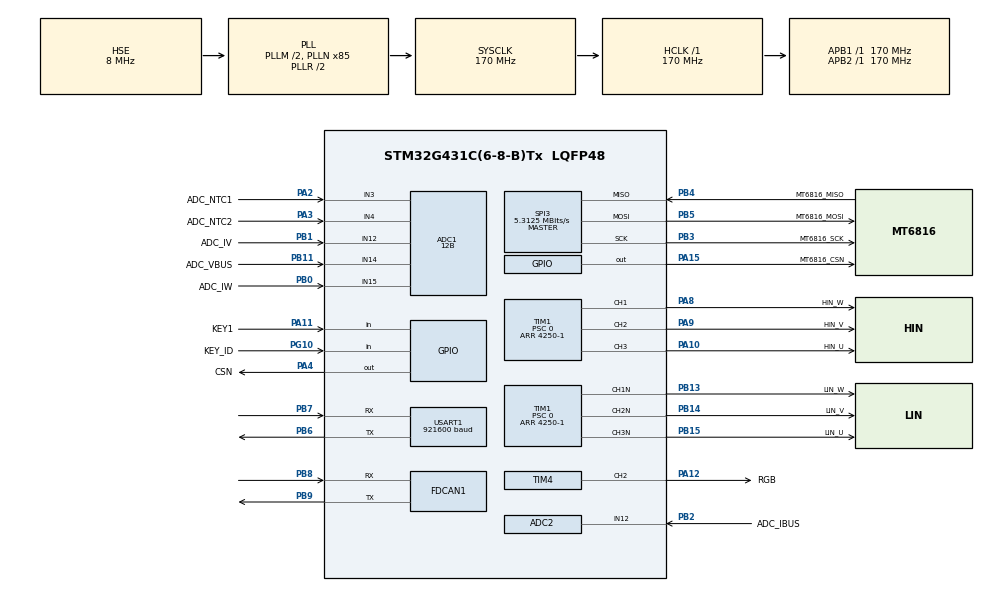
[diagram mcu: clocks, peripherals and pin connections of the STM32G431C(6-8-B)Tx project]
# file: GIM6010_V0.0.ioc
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ADC1.Channel-0\#ChannelRegularConversion=ADC_CHANNEL_14
ADC1.Channel-1\#ChannelRegularConversion=ADC_CHANNEL_3
ADC1.Channel-2\#ChannelRegularConversion=ADC_CHANNEL_4
ADC1.ContinuousConvMode=DISABLE
ADC1.DMAContinuousRequests=DISABLE
ADC1.DiscontinuousConvMode=DISABLE
ADC1.EOCSelection=ADC_EOC_SEQ_CONV
ADC1.EnableInjectedConversion=ENABLE
ADC1.EnableRegularConversion=ENABLE
ADC1.ExternalTrigConv=ADC_SOFTWARE_START
ADC1.ExternalTrigConvEdge=ADC_EXTERNALTRIGCONVEDGE_NONE
ADC1.ExternalTrigInjecConv=ADC_EXTERNALTRIGINJEC_T1_CC4
ADC1.ExternalTrigInjecConvEdge=ADC_EXTERNALTRIGINJECCONV_EDGE_RISING
ADC1.InjNumberOfConversion=3
ADC1.InjectedChannel-1\#ChannelInjectedConversion=ADC_CHANNEL_12
ADC1.InjectedChannel-2\#ChannelInjectedConversion=ADC_CHANNEL_15
ADC1.InjectedChannel-3\#ChannelInjectedConversion=ADC_CHANNEL_14
ADC1.InjectedConvMode=None
ADC1.InjectedOffsetNumber-1\#ChannelInjectedConversion=ADC_OFFSET_NONE
ADC1.InjectedOffsetNumber-2\#ChannelInjectedConversion=ADC_OFFSET_NONE
ADC1.InjectedOffsetNumber-3\#ChannelInjectedConversion=ADC_OFFSET_NONE
ADC1.InjectedRank-1\#ChannelInjectedConversion=1
ADC1.InjectedRank-2\#ChannelInjectedConversion=2
ADC1.InjectedRank-3\#ChannelInjectedConversion=3
ADC1.InjectedSamplingTime-1\#ChannelInjectedConversion=ADC_SAMPLETIME_47CYCLES_5
ADC1.InjectedSamplingTime-2\#ChannelInjectedConversion=ADC_SAMPLETIME_47CYCLES_5
ADC1.InjectedSamplingTime-3\#ChannelInjectedConversion=ADC_SAMPLETIME_47CYCLES_5
ADC1.LowPowerAutoWait=DISABLE
ADC1.NbrOfConversion=3
ADC1.NbrOfConversionFlag=1
ADC1.OffsetNumber-0\#ChannelRegularConversion=ADC_OFFSET_NONE
ADC1.OffsetNumber-1\#ChannelRegularConversion=ADC_OFFSET_NONE
ADC1.OffsetNumber-2\#ChannelRegularConversion=ADC_OFFSET_NONE
ADC1.Overrun=ADC_OVR_DATA_PRESERVED
ADC1.Rank-0\#ChannelRegularConversion=1
ADC1.Rank-1\#ChannelRegularConversion=2
ADC1.Rank-2\#ChannelRegularConversion=3
ADC1.Resolution=ADC_RESOLUTION_12B
ADC1.SamplingTime-0\#ChannelRegularConversion=ADC_SAMPLETIME_47CYCLES_5
ADC1.SamplingTime-1\#ChannelRegularConversion=ADC_SAMPLETIME_47CYCLES_5
ADC1.SamplingTime-2\#ChannelRegularConversion=ADC_SAMPLETIME_47CYCLES_5
ADC1.ScanConvMode=ADC_SCAN_ENABLE
ADC1.SingleDiff-1\#ChannelInjectedConversion=ADC_SINGLE_ENDED
ADC1.SingleDiff-2\#ChannelInjectedConversion=ADC_SINGLE_ENDED
ADC1.SingleDiff-3\#ChannelInjectedConversion=ADC_SINGLE_ENDED
ADC1.master=1
ADC2.Channel-0\#ChannelRegularConversion=ADC_CHANNEL_12
ADC2.ContinuousConvMode=DISABLE
ADC2.DiscontinuousConvMode=DISABLE
ADC2.EnableInjectedConversion=DISABLE
ADC2.EnableRegularConversion=ENABLE
ADC2.ExternalTrigConv=ADC_SOFTWARE_START
ADC2.ExternalTrigConvEdge=ADC_EXTERNALTRIGCONVEDGE_NONE
ADC2.NbrOfConversionFlag=1
ADC2.OffsetNumber-0\#ChannelRegularConversion=ADC_OFFSET_NONE
ADC2.Overrun=ADC_OVR_DATA_PRESERVED
ADC2.Rank-0\#ChannelRegularConversion=1
ADC2.Resolution=ADC_RESOLUTION_12B
ADC2.SamplingTime-0\#ChannelRegularConversion=ADC_SAMPLETIME_47CYCLES_5
Dma.Request0=USART1_TX
Dma.Request1=USART1_RX
Dma.Request2=SPI3_RX
Dma.Request3=SPI3_TX
Dma.Request4=TIM4_CH2
Dma.SPI3_RX.2.Direction=DMA_PERIPH_TO_MEMORY
Dma.SPI3_RX.2.EventEnable=DISABLE
Dma.SPI3_RX.2.Instance=DMA2_Channel1
Dma.SPI3_RX.2.MemDataAlignment=DMA_MDATAALIGN_HALFWORD
Dma.SPI3_RX.2.MemInc=DMA_MINC_ENABLE
Dma.SPI3_RX.2.Mode=DMA_NORMAL
Dma.SPI3_RX.2.PeriphDataAlignment=DMA_PDATAALIGN_HALFWORD
Dma.SPI3_RX.2.PeriphInc=DMA_PINC_DISABLE
Dma.SPI3_RX.2.Polarity=HAL_DMAMUX_REQ_GEN_RISING
Dma.SPI3_RX.2.Priority=DMA_PRIORITY_HIGH
Dma.SPI3_RX.2.RequestNumber=1
Dma.SPI3_RX.2.SignalID=NONE
Dma.SPI3_RX.2.SyncEnable=DISABLE
Dma.SPI3_RX.2.SyncPolarity=HAL_DMAMUX_SYNC_NO_EVENT
Dma.SPI3_RX.2.SyncRequestNumber=1
Dma.SPI3_RX.2.SyncSignalID=NONE
Dma.SPI3_TX.3.Direction=DMA_MEMORY_TO_PERIPH
Dma.SPI3_TX.3.EventEnable=DISABLE
Dma.SPI3_TX.3.Instance=DMA2_Channel2
Dma.SPI3_TX.3.MemDataAlignment=DMA_MDATAALIGN_HALFWORD
Dma.SPI3_TX.3.MemInc=DMA_MINC_ENABLE
Dma.SPI3_TX.3.Mode=DMA_NORMAL
Dma.SPI3_TX.3.PeriphDataAlignment=DMA_PDATAALIGN_HALFWORD
Dma.SPI3_TX.3.PeriphInc=DMA_PINC_DISABLE
Dma.SPI3_TX.3.Polarity=HAL_DMAMUX_REQ_GEN_RISING
Dma.SPI3_TX.3.Priority=DMA_PRIORITY_HIGH
Dma.SPI3_TX.3.RequestNumber=1
Dma.SPI3_TX.3.SignalID=NONE
Dma.SPI3_TX.3.SyncEnable=DISABLE
Dma.SPI3_TX.3.SyncPolarity=HAL_DMAMUX_SYNC_NO_EVENT
Dma.SPI3_TX.3.SyncRequestNumber=1
Dma.SPI3_TX.3.SyncSignalID=NONE
Dma.TIM4_CH2.4.Direction=DMA_PERIPH_TO_MEMORY
Dma.TIM4_CH2.4.EventEnable=DISABLE
Dma.TIM4_CH2.4.Instance=DMA1_Channel1
Dma.TIM4_CH2.4.MemDataAlignment=DMA_MDATAALIGN_HALFWORD
Dma.TIM4_CH2.4.MemInc=DMA_MINC_ENABLE
Dma.TIM4_CH2.4.Mode=DMA_NORMAL
Dma.TIM4_CH2.4.PeriphDataAlignment=DMA_PDATAALIGN_HALFWORD
Dma.TIM4_CH2.4.PeriphInc=DMA_PINC_DISABLE
Dma.TIM4_CH2.4.Polarity=HAL_DMAMUX_REQ_GEN_RISING
Dma.TIM4_CH2.4.Priority=DMA_PRIORITY_LOW
Dma.TIM4_CH2.4.RequestNumber=1
Dma.TIM4_CH2.4.SignalID=NONE
Dma.TIM4_CH2.4.SyncEnable=DISABLE
Dma.TIM4_CH2.4.SyncPolarity=HAL_DMAMUX_SYNC_NO_EVENT
Dma.TIM4_CH2.4.SyncRequestNumber=1
Dma.TIM4_CH2.4.SyncSignalID=NONE
Dma.USART1_RX.1.Direction=DMA_PERIPH_TO_MEMORY
Dma.USART1_RX.1.EventEnable=DISABLE
Dma.USART1_RX.1.Instance=DMA1_Channel4
Dma.USART1_RX.1.MemDataAlignment=DMA_MDATAALIGN_BYTE
Dma.USART1_RX.1.MemInc=DMA_MINC_ENABLE
Dma.USART1_RX.1.Mode=DMA_NORMAL
Dma.USART1_RX.1.PeriphDataAlignment=DMA_PDATAALIGN_BYTE
Dma.USART1_RX.1.PeriphInc=DMA_PINC_DISABLE
Dma.USART1_RX.1.Polarity=HAL_DMAMUX_REQ_GEN_RISING
Dma.USART1_RX.1.Priority=DMA_PRIORITY_LOW
Dma.USART1_RX.1.RequestNumber=1
Dma.USART1_RX.1.SignalID=NONE
Dma.USART1_RX.1.SyncEnable=DISABLE
Dma.USART1_RX.1.SyncPolarity=HAL_DMAMUX_SYNC_NO_EVENT
Dma.USART1_RX.1.SyncRequestNumber=1
Dma.USART1_RX.1.SyncSignalID=NONE
Dma.USART1_TX.0.Direction=DMA_MEMORY_TO_PERIPH
Dma.USART1_TX.0.EventEnable=DISABLE
Dma.USART1_TX.0.Instance=DMA1_Channel2
Dma.USART1_TX.0.MemDataAlignment=DMA_MDATAALIGN_BYTE
Dma.USART1_TX.0.MemInc=DMA_MINC_ENABLE
Dma.USART1_TX.0.Mode=DMA_NORMAL
Dma.USART1_TX.0.PeriphDataAlignment=DMA_PDATAALIGN_BYTE
Dma.USART1_TX.0.PeriphInc=DMA_PINC_DISABLE
Dma.USART1_TX.0.Polarity=HAL_DMAMUX_REQ_GEN_RISING
Dma.USART1_TX.0.Priority=DMA_PRIORITY_LOW
Dma.USART1_TX.0.RequestNumber=1
Dma.USART1_TX.0.SignalID=NONE
Dma.USART1_TX.0.SyncEnable=DISABLE
Dma.USART1_TX.0.SyncPolarity=HAL_DMAMUX_SYNC_NO_EVENT
Dma.USART1_TX.0.SyncRequestNumber=1
Dma.USART1_TX.0.SyncSignalID=NONE
FDCAN1.CalculateBaudRateNominal=999999
FDCAN1.CalculateTimeBitNominal=1000
FDCAN1.CalculateTimeQuantumNominal=5.882352941176471
FDCAN1.NominalPrescaler=1
FDCAN1.NominalTimeSeg1=135
FDCAN1.NominalTimeSeg2=34
Mcu.Family=STM32G4
Mcu.Name=STM32G431C(6-8-B)Tx
Mcu.Package=LQFP48
NVIC.ADC1_2_IRQn=true\:0\:0\:true\:false\:true\:true\:true\:true
NVIC.DMA1_Channel1_IRQn=true\:0\:0\:false\:false\:true\:false\:true\:true
NVIC.DMA1_Channel2_IRQn=true\:3\:0\:true\:false\:true\:false\:true\:true
NVIC.DMA1_Channel4_IRQn=true\:3\:0\:true\:false\:true\:false\:true\:true
NVIC.DMA2_Channel1_IRQn=true\:1\:0\:true\:false\:true\:false\:true\:true
NVIC.DMA2_Channel2_IRQn=true\:1\:0\:true\:false\:true\:false\:true\:true
NVIC.PriorityGroup=NVIC_PRIORITYGROUP_4
NVIC.SPI3_IRQn=true\:1\:0\:true\:false\:true\:true\:true\:true
NVIC.TIM1_BRK_TIM15_IRQn=true\:0\:0\:false\:false\:true\:true\:true\:true
NVIC.TIM1_CC_IRQn=true\:0\:0\:false\:false\:true\:true\:true\:true
NVIC.TIM1_TRG_COM_TIM17_IRQn=true\:0\:0\:false\:false\:true\:true\:true\:true
NVIC.TIM1_UP_TIM16_IRQn=true\:0\:0\:false\:false\:true\:true\:true\:true
NVIC.TIM2_IRQn=true\:2\:0\:true\:false\:true\:true\:true\:true
NVIC.TIM4_IRQn=true\:0\:0\:false\:false\:true\:true\:true\:true
NVIC.USART1_IRQn=true\:3\:0\:true\:false\:true\:true\:true\:true
PA10.GPIO_Label=HIN_U
PA10.Signal=S_TIM1_CH3
PA11.GPIO_Label=KEY1
PA11.Signal=GPIO_Input
PA12.GPIO_Label=RGB
PA12.Signal=S_TIM4_CH2
PA13.Mode=Serial_Wire
PA13.Signal=SYS_JTMS-SWDIO
PA14.Mode=Serial_Wire
PA14.Signal=SYS_JTCK-SWCLK
PA15.GPIO_Label=MT6816_CSN
PA15.GPIO_Speed=GPIO_SPEED_FREQ_VERY_HIGH
PA15.PinState=GPIO_PIN_SET
PA15.Signal=GPIO_Output
PA2.GPIO_Label=ADC_NTC1
PA2.Mode=IN3-Single-Ended
PA2.Signal=ADC1_IN3
PA3.GPIO_Label=ADC_NTC2
PA3.Mode=IN4-Single-Ended
PA3.Signal=ADC1_IN4
PA4.GPIO_Label=CSN
PA4.Signal=GPIO_Output
PA8.GPIO_Label=HIN_W
PA8.Signal=S_TIM1_CH1
PA9.GPIO_Label=HIN_V
PA9.Signal=S_TIM1_CH2
PB0.GPIO_Label=ADC_IW
PB0.Mode=IN15-Single-Ended
PB0.Signal=ADC1_IN15
PB1.GPIO_Label=ADC_IV
PB1.Mode=IN12-Single-Ended
PB1.Signal=ADC1_IN12
PB11.GPIO_Label=ADC_VBUS
PB11.Mode=IN14-Single-Ended
PB11.Signal=ADC1_IN14
PB13.GPIO_Label=LIN_W
PB13.Mode=PWM Generation1 CH1 CH1N
PB13.Signal=TIM1_CH1N
PB14.GPIO_Label=LIN_V
PB14.Mode=PWM Generation2 CH2 CH2N
PB14.Signal=TIM1_CH2N
PB15.GPIO_Label=LIN_U
PB15.Mode=PWM Generation3 CH3 CH3N
PB15.Signal=TIM1_CH3N
PB2.GPIO_Label=ADC_IBUS
PB2.Mode=IN12-Single-Ended
PB2.Signal=ADC2_IN12
PB3.GPIO_Label=MT6816_SCK
PB3.Mode=Full_Duplex_Master
PB3.Signal=SPI3_SCK
PB4.GPIO_Label=MT6816_MISO
PB4.Mode=Full_Duplex_Master
PB4.Signal=SPI3_MISO
PB5.GPIO_Label=MT6816_MOSI
PB5.Mode=Full_Duplex_Master
PB5.Signal=SPI3_MOSI
PB6.Mode=Asynchronous
PB6.Signal=USART1_TX
PB7.Mode=Asynchronous
PB7.Signal=USART1_RX
PB8-BOOT0.Mode=FDCAN_Activate
PB8-BOOT0.Signal=FDCAN1_RX
PB9.Mode=FDCAN_Activate
PB9.Signal=FDCAN1_TX
PF0-OSC_IN.Mode=HSE-External-Oscillator
PF0-OSC_IN.Signal=RCC_OSC_IN
PF1-OSC_OUT.Mode=HSE-External-Oscillator
PF1-OSC_OUT.Signal=RCC_OSC_OUT
PG10-NRST.GPIO_Label=KEY_ID
PG10-NRST.GPIO_PuPd=GPIO_PULLUP
PG10-NRST.Signal=GPIO_Input
ProjectManager.HeapSize=0x200
ProjectManager.StackSize=0x400
ProjectManager.TargetToolchain=MDK-ARM V5.32
RCC.ADC12Freq_Value=170000000
RCC.AHBFreq_Value=170000000
RCC.APB1Freq_Value=170000000
RCC.APB1TimFreq_Value=170000000
RCC.APB2Freq_Value=170000000
RCC.APB2TimFreq_Value=170000000
RCC.CortexFreq_Value=170000000
RCC.EXTERNAL_CLOCK_VALUE=12288000
RCC.HCLKFreq_Value=170000000
RCC.HSE_VALUE=8000000
RCC.HSI48_VALUE=48000000
RCC.HSI_VALUE=16000000
RCC.LSE_VALUE=32768
RCC.PLLM=RCC_PLLM_DIV2
RCC.PLLN=85
RCC.PLLSourceVirtual=RCC_PLLSOURCE_HSE
RCC.SYSCLKFreq_VALUE=170000000
RCC.SYSCLKSource=RCC_SYSCLKSOURCE_PLLCLK
RCC.USBFreq_Value=170000000
RCC.VCOOutputFreq_Value=340000000
SH.S_TIM1_CH1.0=TIM1_CH1,PWM Generation1 CH1 CH1N
SH.S_TIM1_CH2.0=TIM1_CH2,PWM Generation2 CH2 CH2N
SH.S_TIM1_CH3.0=TIM1_CH3,PWM Generation3 CH3 CH3N
SH.S_TIM4_CH2.0=TIM4_CH2,PWM Generation2 CH2
SPI3.BaudRatePrescaler=SPI_BAUDRATEPRESCALER_32
SPI3.CLKPhase=SPI_PHASE_2EDGE
SPI3.CLKPolarity=SPI_POLARITY_HIGH
SPI3.CalculateBaudRate=5.3125 MBits/s
SPI3.DataSize=SPI_DATASIZE_16BIT
SPI3.Direction=SPI_DIRECTION_2LINES
SPI3.Mode=SPI_MODE_MASTER
SPI3.VirtualType=VM_MASTER
TIM1.AutoReloadPreload=TIM_AUTORELOAD_PRELOAD_ENABLE
TIM1.AutomaticOutput=TIM_AUTOMATICOUTPUT_DISABLE
TIM1.BreakState=TIM_BREAK_DISABLE
TIM1.Channel-PWM\ Generation1\ CH1\ CH1N=TIM_CHANNEL_1
TIM1.Channel-PWM\ Generation2\ CH2\ CH2N=TIM_CHANNEL_2
TIM1.Channel-PWM\ Generation3\ CH3\ CH3N=TIM_CHANNEL_3
TIM1.Channel-PWM\ Generation4\ No\ Output=TIM_CHANNEL_4
TIM1.ClockDivision=TIM_CLOCKDIVISION_DIV2
TIM1.CounterMode=TIM_COUNTERMODE_CENTERALIGNED1
TIM1.DeadTime=9
TIM1.OCMode_PWM-PWM\ Generation4\ No\ Output=TIM_OCMODE_PWM2
TIM1.OffStateIDLEMode=TIM_OSSI_ENABLE
TIM1.OffStateRunMode=TIM_OSSR_ENABLE
TIM1.PeriodNoDither=4250-1
TIM1.Prescaler=0
TIM1.RepetitionCounter=0
TIM1.TIM_MasterOutputTrigger=TIM_TRGO_OC4REF
TIM2.Channel-PWM\ Generation1\ No\ Output=TIM_CHANNEL_1
TIM2.PeriodNoDither=1000-1
TIM2.Prescaler=170-1
TIM4.Channel-PWM\ Generation2\ CH2=TIM_CHANNEL_2
USART1.BaudRate=921600
USART1.VirtualMode-Asynchronous=VM_ASYNC
VP_SYS_VS_DBSignals.Mode=DisableDeadBatterySignals
VP_TIM1_VS_no_output4.Mode=PWM Generation4 No Output
VP_TIM2_VS_no_output1.Mode=PWM Generation1 No Output
board=custom

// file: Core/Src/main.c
/* USER CODE BEGIN Header */
/**
  ******************************************************************************
  * @file           : main.c
  * @brief          : Main program body
  ******************************************************************************
  * @attention
  *
  * Copyright (c) 2026 STMicroelectronics.
  * All rights reserved.
  *
  * This software is licensed under terms that can be found in the LICENSE file
  * in the root directory of this software component.
  * If no LICENSE file comes with this software, it is provided AS-IS.
  *
  ******************************************************************************
  */
/* USER CODE END Header */
#include "main.h"
#include "adc.h"
#include "dma.h"
#include "fdcan.h"
#include "spi.h"
#include "tim.h"
#include "usart.h"
#include "gpio.h"
#include "SguanFOC.h"

void SystemClock_Config(void);

int main(void)
{

  /* MCU Configuration--------------------------------------------------------*/

  /* Reset of all peripherals, Initializes the Flash interface and the Systick. */
  HAL_Init();

  /* Configure the system clock */
  SystemClock_Config();

  /* Initialize all configured peripherals */
  MX_GPIO_Init();
  MX_DMA_Init();
  MX_ADC1_Init();
  MX_ADC2_Init();
  MX_FDCAN1_Init();
  MX_SPI3_Init();
  MX_TIM1_Init();
  MX_TIM4_Init();
  MX_USART1_UART_Init();
  MX_TIM2_Init();

  /* Infinite loop */
  while (1)
  {

    /* USER CODE BEGIN 3 */
    SguanFOC_main_Loop();
  }
  /* USER CODE END 3 */
}

void SystemClock_Config(void)
{
  RCC_OscInitTypeDef RCC_OscInitStruct = {0};
  RCC_ClkInitTypeDef RCC_ClkInitStruct = {0};

  /** Configure the main internal regulator output voltage
  */
  HAL_PWREx_ControlVoltageScaling(PWR_REGULATOR_VOLTAGE_SCALE1_BOOST);

  /** Initializes the RCC Oscillators according to the specified parameters
  * in the RCC_OscInitTypeDef structure.
  */
  RCC_OscInitStruct.OscillatorType = RCC_OSCILLATORTYPE_HSE;
  RCC_OscInitStruct.HSEState = RCC_HSE_ON;
  RCC_OscInitStruct.PLL.PLLState = RCC_PLL_ON;
  RCC_OscInitStruct.PLL.PLLSource = RCC_PLLSOURCE_HSE;
  RCC_OscInitStruct.PLL.PLLM = RCC_PLLM_DIV2;
  RCC_OscInitStruct.PLL.PLLN = 85;
  RCC_OscInitStruct.PLL.PLLP = RCC_PLLP_DIV2;
  RCC_OscInitStruct.PLL.PLLQ = RCC_PLLQ_DIV2;
  RCC_OscInitStruct.PLL.PLLR = RCC_PLLR_DIV2;
  if (HAL_RCC_OscConfig(&RCC_OscInitStruct) != HAL_OK)
  {
    Error_Handler();
  }

  /** Initializes the CPU, AHB and APB buses clocks
  */
  RCC_ClkInitStruct.ClockType = RCC_CLOCKTYPE_HCLK|RCC_CLOCKTYPE_SYSCLK
                              |RCC_CLOCKTYPE_PCLK1|RCC_CLOCKTYPE_PCLK2;
  RCC_ClkInitStruct.SYSCLKSource = RCC_SYSCLKSOURCE_PLLCLK;
  RCC_ClkInitStruct.AHBCLKDivider = RCC_SYSCLK_DIV1;
  RCC_ClkInitStruct.APB1CLKDivider = RCC_HCLK_DIV1;
  RCC_ClkInitStruct.APB2CLKDivider = RCC_HCLK_DIV1;

  if (HAL_RCC_ClockConfig(&RCC_ClkInitStruct, FLASH_LATENCY_4) != HAL_OK)
  {
    Error_Handler();
  }
}

void Error_Handler(void)
{
  __disable_irq();
  while (1)
  {
  }
}
